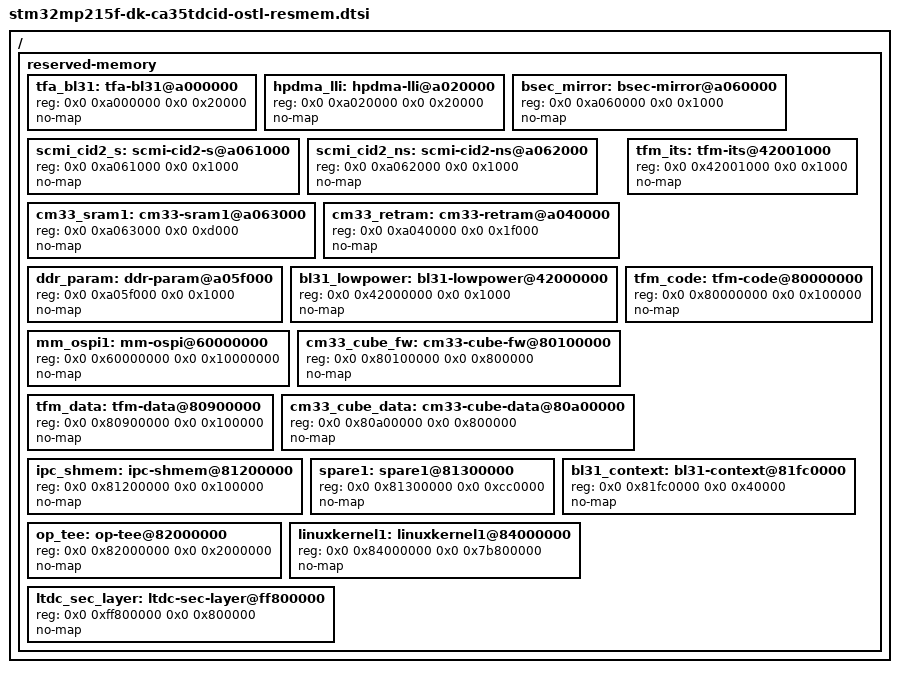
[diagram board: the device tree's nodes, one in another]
// SPDX-License-Identifier: (GPL-2.0-only OR BSD-3-Clause)
/*
 * Copyright (C) STMicroelectronics 2024 - All Rights Reserved
 * Author: Loic Pallardy loic.pallardy@foss.st.com for STMicroelectronics.
 */

/*
 * stm32mp215f reserved memory device tree configuration
 * Project : ostl
 * Generated by XLmx tool version 2.2 - 11/5/2024 4:33:19 PM
 */

/ {
	reserved-memory {
		#address-cells = <2>;
		#size-cells = <2>;
		ranges;

		/* Internal RAM reserved memory declaration */
		tfa_bl31: tfa-bl31@a000000 {
			reg = <0x0 0xa000000 0x0 0x20000>;
			no-map;
		};

		hpdma_lli: hpdma-lli@a020000 {
			reg = <0x0 0xa020000 0x0 0x20000>;
			no-map;
		};

		bsec_mirror: bsec-mirror@a060000 {
			reg = <0x0 0xa060000 0x0 0x1000>;
			no-map;
		};

		scmi_cid2_s: scmi-cid2-s@a061000 {
			reg = <0x0 0xa061000 0x0 0x1000>;
			no-map;
		};

		scmi_cid2_ns: scmi-cid2-ns@a062000 {
			reg = <0x0 0xa062000 0x0 0x1000>;
			no-map;
		};

		cm33_sram1: cm33-sram1@a063000 {
			reg = <0x0 0xa063000 0x0 0xd000>;
			no-map;
		};

		cm33_retram: cm33-retram@a040000 {
			reg = <0x0 0xa040000 0x0 0x1f000>;
			no-map;
		};

		ddr_param: ddr-param@a05f000 {
			reg = <0x0 0xa05f000 0x0 0x1000>;
			no-map;
		};

		/* Backup RAM reserved memory declaration */
		bl31_lowpower: bl31-lowpower@42000000 {
			reg = <0x0 0x42000000 0x0 0x1000>;
			no-map;
		};

		tfm_its: tfm-its@42001000 {
			reg = <0x0 0x42001000 0x0 0x1000>;
			no-map;
		};

		/* Octo Memory Manager reserved memory declaration */
		mm_ospi1: mm-ospi@60000000 {
			reg = <0x0 0x60000000 0x0 0x10000000>;
			no-map;
		};

		/* DDR reserved memory declaration */
		tfm_code: tfm-code@80000000 {
			reg = <0x0 0x80000000 0x0 0x100000>;
			no-map;
		};

		cm33_cube_fw: cm33-cube-fw@80100000 {
			reg = <0x0 0x80100000 0x0 0x800000>;
			no-map;
		};

		tfm_data: tfm-data@80900000 {
			reg = <0x0 0x80900000 0x0 0x100000>;
			no-map;
		};

		cm33_cube_data: cm33-cube-data@80a00000 {
			reg = <0x0 0x80a00000 0x0 0x800000>;
			no-map;
		};

		ipc_shmem: ipc-shmem@81200000 {
			reg = <0x0 0x81200000 0x0 0x100000>;
			no-map;
		};

		spare1: spare1@81300000 {
			reg = <0x0 0x81300000 0x0 0xcc0000>;
			no-map;
		};

		bl31_context: bl31-context@81fc0000 {
			reg = <0x0 0x81fc0000 0x0 0x40000>;
			no-map;
		};

		op_tee: op-tee@82000000 {
			reg = <0x0 0x82000000 0x0 0x2000000>;
			no-map;
		};

		linuxkernel1: linuxkernel1@84000000 {
			reg = <0x0 0x84000000 0x0 0x7b800000>;
			no-map;
		};

		ltdc_sec_layer: ltdc-sec-layer@ff800000 {
			reg = <0x0 0xff800000 0x0 0x800000>;
			no-map;
		};

	};
};
